# Espressif register map
File version: 1.0
CPU: Xtensa LX6 1, little endian, no MPU, FPU, 3 interrupt priority bits
Registers are 32-bit, access not given, reset 0x0 unless marked. A register's access mark holds for its fields unless they carry their own. Offsets are from the block's base; [hi:lo] are bit positions; {n}, {i} and the like mark numbered series.

## SPI0
Base 0x3FF43000
Same registers: SPI1 0x3FF42000, SPI2 0x3FF64000, SPI3 0x3FF65000
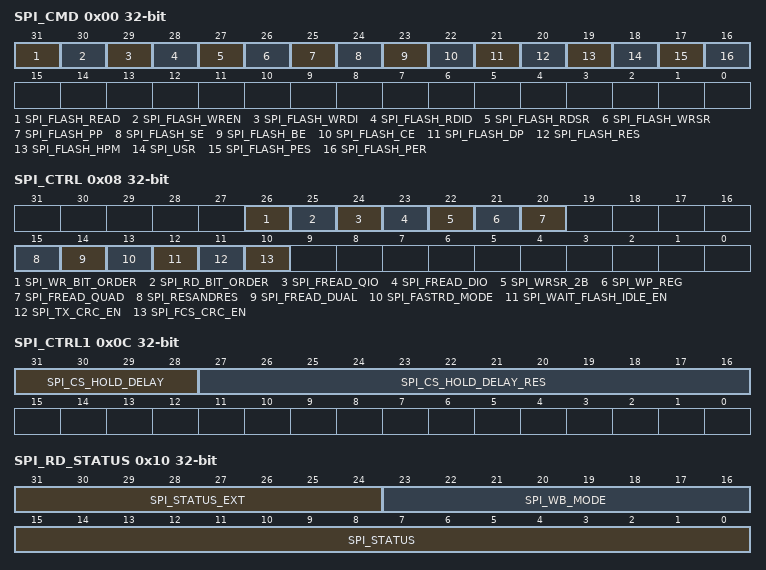
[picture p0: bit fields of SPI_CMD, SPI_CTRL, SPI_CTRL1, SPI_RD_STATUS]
0x00 SPI_CMD
  [31] SPI_FLASH_READ, [30] SPI_FLASH_WREN, [29] SPI_FLASH_WRDI, [28] SPI_FLASH_RDID, [27] SPI_FLASH_RDSR, [26] SPI_FLASH_WRSR, [25] SPI_FLASH_PP, [24] SPI_FLASH_SE, [23] SPI_FLASH_BE, [22] SPI_FLASH_CE, [21] SPI_FLASH_DP, [20] SPI_FLASH_RES, [19] SPI_FLASH_HPM, [18] SPI_USR, [17] SPI_FLASH_PES, [16] SPI_FLASH_PER
0x08 SPI_CTRL
  [26] SPI_WR_BIT_ORDER, [25] SPI_RD_BIT_ORDER, [24] SPI_FREAD_QIO, [23] SPI_FREAD_DIO, [22] SPI_WRSR_2B, [21] SPI_WP_REG, [20] SPI_FREAD_QUAD, [15] SPI_RESANDRES, [14] SPI_FREAD_DUAL, [13] SPI_FASTRD_MODE, [12] SPI_WAIT_FLASH_IDLE_EN, [11] SPI_TX_CRC_EN, [10] SPI_FCS_CRC_EN
0x0C SPI_CTRL1
  [31:28] SPI_CS_HOLD_DELAY, [27:16] SPI_CS_HOLD_DELAY_RES
0x10 SPI_RD_STATUS
  [31:24] SPI_STATUS_EXT, [23:16] SPI_WB_MODE, [15:0] SPI_STATUS
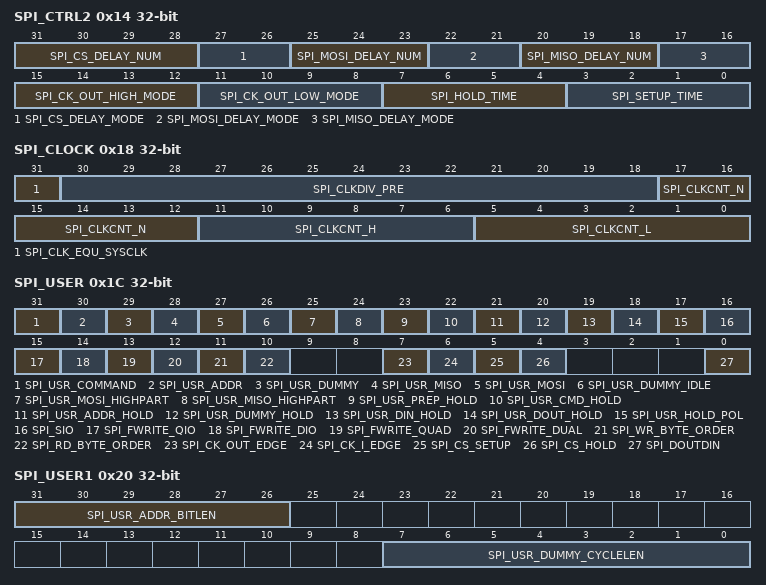
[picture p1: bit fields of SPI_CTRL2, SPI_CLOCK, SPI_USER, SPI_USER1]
0x14 SPI_CTRL2
  [31:28] SPI_CS_DELAY_NUM, [27:26] SPI_CS_DELAY_MODE, [25:23] SPI_MOSI_DELAY_NUM, [22:21] SPI_MOSI_DELAY_MODE, [20:18] SPI_MISO_DELAY_NUM, [17:16] SPI_MISO_DELAY_MODE, [15:12] SPI_CK_OUT_HIGH_MODE, [11:8] SPI_CK_OUT_LOW_MODE, [7:4] SPI_HOLD_TIME, [3:0] SPI_SETUP_TIME
0x18 SPI_CLOCK
  [31] SPI_CLK_EQU_SYSCLK, [30:18] SPI_CLKDIV_PRE, [17:12] SPI_CLKCNT_N, [11:6] SPI_CLKCNT_H, [5:0] SPI_CLKCNT_L
0x1C SPI_USER
  [31] SPI_USR_COMMAND, [30] SPI_USR_ADDR, [29] SPI_USR_DUMMY, [28] SPI_USR_MISO, [27] SPI_USR_MOSI, [26] SPI_USR_DUMMY_IDLE, [25] SPI_USR_MOSI_HIGHPART, [24] SPI_USR_MISO_HIGHPART, [23] SPI_USR_PREP_HOLD, [22] SPI_USR_CMD_HOLD, [21] SPI_USR_ADDR_HOLD, [20] SPI_USR_DUMMY_HOLD, [19] SPI_USR_DIN_HOLD, [18] SPI_USR_DOUT_HOLD, [17] SPI_USR_HOLD_POL, [16] SPI_SIO, [15] SPI_FWRITE_QIO, [14] SPI_FWRITE_DIO, [13] SPI_FWRITE_QUAD, [12] SPI_FWRITE_DUAL, [11] SPI_WR_BYTE_ORDER, [10] SPI_RD_BYTE_ORDER, [7] SPI_CK_OUT_EDGE, [6] SPI_CK_I_EDGE, [5] SPI_CS_SETUP, [4] SPI_CS_HOLD, [0] SPI_DOUTDIN
0x20 SPI_USER1
  [31:26] SPI_USR_ADDR_BITLEN, [7:0] SPI_USR_DUMMY_CYCLELEN
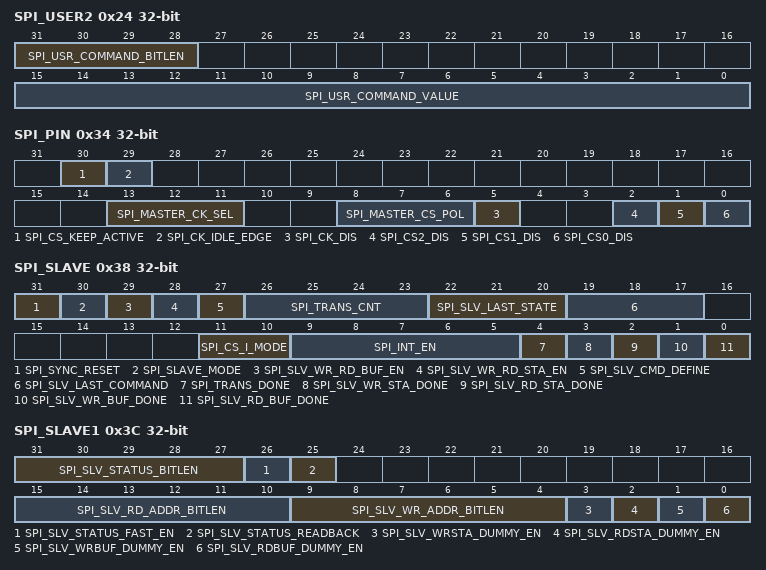
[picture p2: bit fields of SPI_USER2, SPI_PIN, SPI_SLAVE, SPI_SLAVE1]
0x24 SPI_USER2
  [31:28] SPI_USR_COMMAND_BITLEN, [15:0] SPI_USR_COMMAND_VALUE
0x28 SPI_MOSI_DLEN
  [23:0] SPI_USR_MOSI_DBITLEN
0x2C SPI_MISO_DLEN
  [23:0] SPI_USR_MISO_DBITLEN
0x30 SPI_SLV_WR_STATUS
  [31:0] SPI_SLV_WR_ST
0x34 SPI_PIN
  [30] SPI_CS_KEEP_ACTIVE, [29] SPI_CK_IDLE_EDGE, [13:11] SPI_MASTER_CK_SEL, [8:6] SPI_MASTER_CS_POL, [5] SPI_CK_DIS, [2] SPI_CS2_DIS, [1] SPI_CS1_DIS, [0] SPI_CS0_DIS
0x38 SPI_SLAVE
  [31] SPI_SYNC_RESET, [30] SPI_SLAVE_MODE, [29] SPI_SLV_WR_RD_BUF_EN, [28] SPI_SLV_WR_RD_STA_EN, [27] SPI_SLV_CMD_DEFINE, [26:23] SPI_TRANS_CNT, [22:20] SPI_SLV_LAST_STATE, [19:17] SPI_SLV_LAST_COMMAND, [11:10] SPI_CS_I_MODE, [9:5] SPI_INT_EN, [4] SPI_TRANS_DONE, [3] SPI_SLV_WR_STA_DONE, [2] SPI_SLV_RD_STA_DONE, [1] SPI_SLV_WR_BUF_DONE, [0] SPI_SLV_RD_BUF_DONE
0x3C SPI_SLAVE1
  [31:27] SPI_SLV_STATUS_BITLEN, [26] SPI_SLV_STATUS_FAST_EN, [25] SPI_SLV_STATUS_READBACK, [15:10] SPI_SLV_RD_ADDR_BITLEN, [9:4] SPI_SLV_WR_ADDR_BITLEN, [3] SPI_SLV_WRSTA_DUMMY_EN, [2] SPI_SLV_RDSTA_DUMMY_EN, [1] SPI_SLV_WRBUF_DUMMY_EN, [0] SPI_SLV_RDBUF_DUMMY_EN
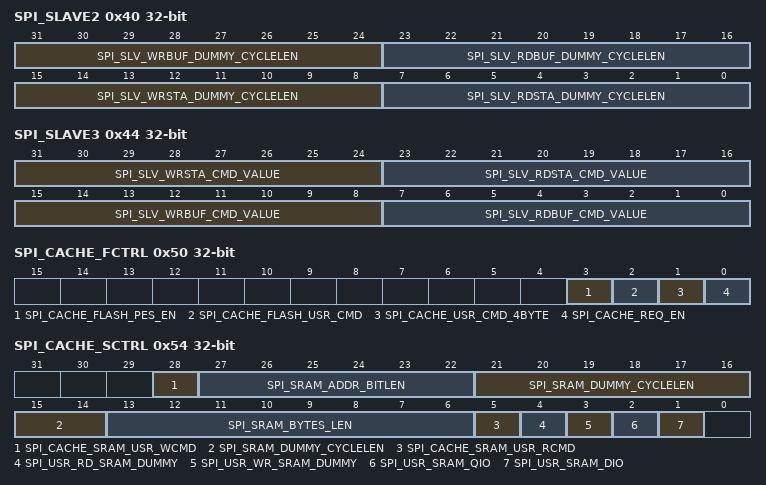
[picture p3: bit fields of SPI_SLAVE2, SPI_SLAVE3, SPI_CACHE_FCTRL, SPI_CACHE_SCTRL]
0x40 SPI_SLAVE2
  [31:24] SPI_SLV_WRBUF_DUMMY_CYCLELEN, [23:16] SPI_SLV_RDBUF_DUMMY_CYCLELEN, [15:8] SPI_SLV_WRSTA_DUMMY_CYCLELEN, [7:0] SPI_SLV_RDSTA_DUMMY_CYCLELEN
0x44 SPI_SLAVE3
  [31:24] SPI_SLV_WRSTA_CMD_VALUE, [23:16] SPI_SLV_RDSTA_CMD_VALUE, [15:8] SPI_SLV_WRBUF_CMD_VALUE, [7:0] SPI_SLV_RDBUF_CMD_VALUE
0x48 SPI_SLV_WRBUF_DLEN
  [23:0] SPI_SLV_WRBUF_DBITLEN
0x4C SPI_SLV_RDBUF_DLEN
  [23:0] SPI_SLV_RDBUF_DBITLEN
0x50 SPI_CACHE_FCTRL
  [3] SPI_CACHE_FLASH_PES_EN, [2] SPI_CACHE_FLASH_USR_CMD, [1] SPI_CACHE_USR_CMD_4BYTE, [0] SPI_CACHE_REQ_EN
0x54 SPI_CACHE_SCTRL
  [28] SPI_CACHE_SRAM_USR_WCMD, [27:22] SPI_SRAM_ADDR_BITLEN, [21:14] SPI_SRAM_DUMMY_CYCLELEN, [13:6] SPI_SRAM_BYTES_LEN, [5] SPI_CACHE_SRAM_USR_RCMD, [4] SPI_USR_RD_SRAM_DUMMY, [3] SPI_USR_WR_SRAM_DUMMY, [2] SPI_USR_SRAM_QIO, [1] SPI_USR_SRAM_DIO
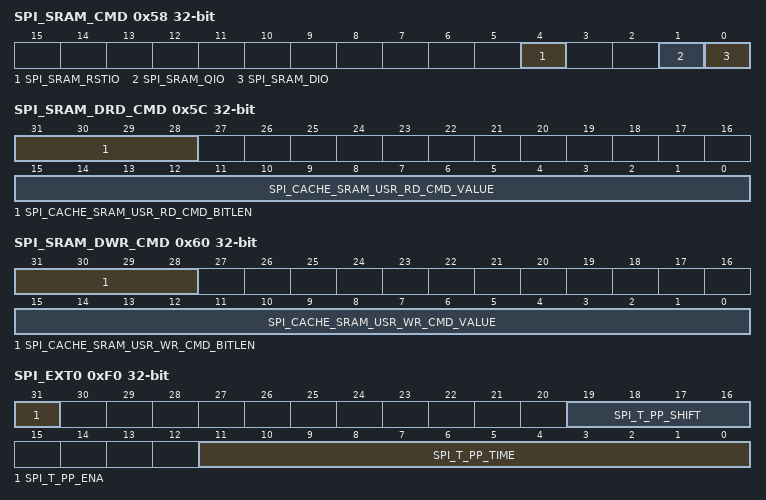
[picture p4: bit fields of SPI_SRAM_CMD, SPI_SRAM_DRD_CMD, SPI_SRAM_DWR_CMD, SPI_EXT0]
0x58 SPI_SRAM_CMD
  [4] SPI_SRAM_RSTIO, [1] SPI_SRAM_QIO, [0] SPI_SRAM_DIO
0x5C SPI_SRAM_DRD_CMD
  [31:28] SPI_CACHE_SRAM_USR_RD_CMD_BITLEN, [15:0] SPI_CACHE_SRAM_USR_RD_CMD_VALUE
0x60 SPI_SRAM_DWR_CMD
  [31:28] SPI_CACHE_SRAM_USR_WR_CMD_BITLEN, [15:0] SPI_CACHE_SRAM_USR_WR_CMD_VALUE
0x64 SPI_SLV_RD_BIT
  [23:0] SPI_SLV_RDATA_BIT
{0x80+4i} SPI_W{i} (i=0..15)
  [31:0] SPI_BUF{i}
0xC0 SPI_TX_CRC
  [31:0] SPI_TX_CRC_DATA
0xF0 SPI_EXT0
  [31] SPI_T_PP_ENA, [19:16] SPI_T_PP_SHIFT, [11:0] SPI_T_PP_TIME
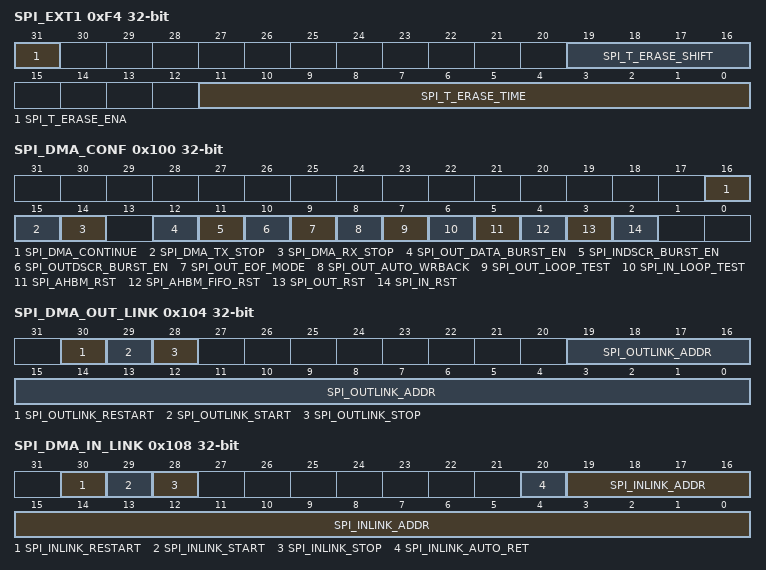
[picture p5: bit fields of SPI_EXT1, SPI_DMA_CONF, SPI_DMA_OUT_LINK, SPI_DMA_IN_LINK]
0xF4 SPI_EXT1
  [31] SPI_T_ERASE_ENA, [19:16] SPI_T_ERASE_SHIFT, [11:0] SPI_T_ERASE_TIME
0xF8 SPI_EXT2
  [2:0] SPI_ST
0xFC SPI_EXT3
  [1:0] SPI_INT_HOLD_ENA
0x100 SPI_DMA_CONF
  [16] SPI_DMA_CONTINUE, [15] SPI_DMA_TX_STOP, [14] SPI_DMA_RX_STOP, [12] SPI_OUT_DATA_BURST_EN, [11] SPI_INDSCR_BURST_EN, [10] SPI_OUTDSCR_BURST_EN, [9] SPI_OUT_EOF_MODE, [8] SPI_OUT_AUTO_WRBACK, [7] SPI_OUT_LOOP_TEST, [6] SPI_IN_LOOP_TEST, [5] SPI_AHBM_RST, [4] SPI_AHBM_FIFO_RST, [3] SPI_OUT_RST, [2] SPI_IN_RST
0x104 SPI_DMA_OUT_LINK
  [30] SPI_OUTLINK_RESTART, [29] SPI_OUTLINK_START, [28] SPI_OUTLINK_STOP, [19:0] SPI_OUTLINK_ADDR
0x108 SPI_DMA_IN_LINK
  [30] SPI_INLINK_RESTART, [29] SPI_INLINK_START, [28] SPI_INLINK_STOP, [20] SPI_INLINK_AUTO_RET, [19:0] SPI_INLINK_ADDR
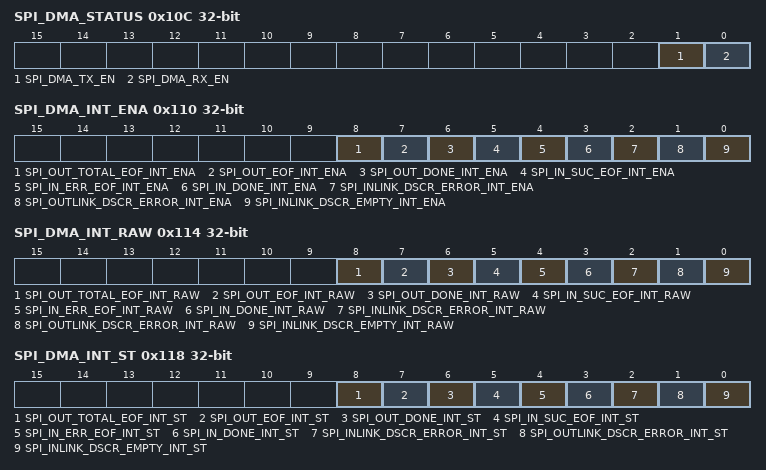
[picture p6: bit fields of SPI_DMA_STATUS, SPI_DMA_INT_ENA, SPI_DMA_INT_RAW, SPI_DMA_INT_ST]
0x10C SPI_DMA_STATUS
  [1] SPI_DMA_TX_EN, [0] SPI_DMA_RX_EN
0x110 SPI_DMA_INT_ENA
  [8] SPI_OUT_TOTAL_EOF_INT_ENA, [7] SPI_OUT_EOF_INT_ENA, [6] SPI_OUT_DONE_INT_ENA, [5] SPI_IN_SUC_EOF_INT_ENA, [4] SPI_IN_ERR_EOF_INT_ENA, [3] SPI_IN_DONE_INT_ENA, [2] SPI_INLINK_DSCR_ERROR_INT_ENA, [1] SPI_OUTLINK_DSCR_ERROR_INT_ENA, [0] SPI_INLINK_DSCR_EMPTY_INT_ENA
0x114 SPI_DMA_INT_RAW
  [8] SPI_OUT_TOTAL_EOF_INT_RAW, [7] SPI_OUT_EOF_INT_RAW, [6] SPI_OUT_DONE_INT_RAW, [5] SPI_IN_SUC_EOF_INT_RAW, [4] SPI_IN_ERR_EOF_INT_RAW, [3] SPI_IN_DONE_INT_RAW, [2] SPI_INLINK_DSCR_ERROR_INT_RAW, [1] SPI_OUTLINK_DSCR_ERROR_INT_RAW, [0] SPI_INLINK_DSCR_EMPTY_INT_RAW
0x118 SPI_DMA_INT_ST
  [8] SPI_OUT_TOTAL_EOF_INT_ST, [7] SPI_OUT_EOF_INT_ST, [6] SPI_OUT_DONE_INT_ST, [5] SPI_IN_SUC_EOF_INT_ST, [4] SPI_IN_ERR_EOF_INT_ST, [3] SPI_IN_DONE_INT_ST, [2] SPI_INLINK_DSCR_ERROR_INT_ST, [1] SPI_OUTLINK_DSCR_ERROR_INT_ST, [0] SPI_INLINK_DSCR_EMPTY_INT_ST
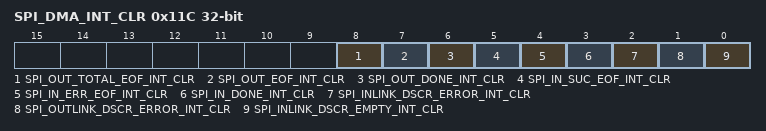
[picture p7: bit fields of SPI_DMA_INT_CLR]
0x11C SPI_DMA_INT_CLR
  [8] SPI_OUT_TOTAL_EOF_INT_CLR, [7] SPI_OUT_EOF_INT_CLR, [6] SPI_OUT_DONE_INT_CLR, [5] SPI_IN_SUC_EOF_INT_CLR, [4] SPI_IN_ERR_EOF_INT_CLR, [3] SPI_IN_DONE_INT_CLR, [2] SPI_INLINK_DSCR_ERROR_INT_CLR, [1] SPI_OUTLINK_DSCR_ERROR_INT_CLR, [0] SPI_INLINK_DSCR_EMPTY_INT_CLR
0x120 SPI_IN_ERR_EOF_DES_ADDR
  [31:0] SPI_DMA_IN_ERR_EOF_DES_ADDR
0x124 SPI_IN_SUC_EOF_DES_ADDR
  [31:0] SPI_DMA_IN_SUC_EOF_DES_ADDR
0x128 SPI_INLINK_DSCR
  [31:0] SPI_DMA_INLINK_DSCR
0x12C SPI_INLINK_DSCR_BF0
  [31:0] SPI_DMA_INLINK_DSCR_BF0
0x130 SPI_INLINK_DSCR_BF1
  [31:0] SPI_DMA_INLINK_DSCR_BF1
0x134 SPI_OUT_EOF_BFR_DES_ADDR
  [31:0] SPI_DMA_OUT_EOF_BFR_DES_ADDR
0x138 SPI_OUT_EOF_DES_ADDR
  [31:0] SPI_DMA_OUT_EOF_DES_ADDR
0x13C SPI_OUTLINK_DSCR
  [31:0] SPI_DMA_OUTLINK_DSCR
0x140 SPI_OUTLINK_DSCR_BF0
  [31:0] SPI_DMA_OUTLINK_DSCR_BF0
0x144 SPI_OUTLINK_DSCR_BF1
  [31:0] SPI_DMA_OUTLINK_DSCR_BF1
0x148 SPI_DMA_RSTATUS
  [31:0] SPI_DMA_OUT_STATUS
0x14C SPI_DMA_TSTATUS
  [31:0] SPI_DMA_IN_STATUS
0x3FC SPI_DATE
  [27:0] SPI_DATE
